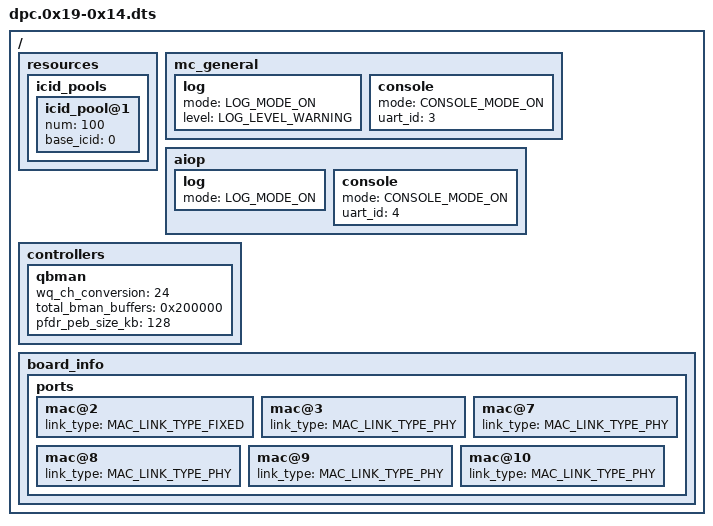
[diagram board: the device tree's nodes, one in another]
/*
 * Copyright 2017 NXP
 *
 * Redistribution and use in source and binary forms, with or without
 * modification, are permitted provided that the following conditions are met:
 *   * Redistributions of source code must retain the above copyright
 *     notice, this list of conditions and the following disclaimer.
 *   * Redistributions in binary form must reproduce the above copyright
 *     notice, this list of conditions and the following disclaimer in the
 *     documentation and/or other materials provided with the distribution.
 *   * Neither the name of the above-listed copyright holders nor the
 *     names of any contributors may be used to endorse or promote products
 *     derived from this software without specific prior written permission.
 *
 * THIS SOFTWARE IS PROVIDED BY THE COPYRIGHT HOLDERS AND CONTRIBUTORS "AS IS"
 * AND ANY EXPRESS OR IMPLIED WARRANTIES, INCLUDING, BUT NOT LIMITED TO, THE
 * IMPLIED WARRANTIES OF MERCHANTABILITY AND FITNESS FOR A PARTICULAR PURPOSE
 * ARE DISCLAIMED. IN NO EVENT SHALL THE COPYRIGHT HOLDERS OR CONTRIBUTORS BE
 * LIABLE FOR ANY DIRECT, INDIRECT, INCIDENTAL, SPECIAL, EXEMPLARY, OR
 * CONSEQUENTIAL DAMAGES (INCLUDING, BUT NOT LIMITED TO, PROCUREMENT OF
 * SUBSTITUTE GOODS OR SERVICES; LOSS OF USE, DATA, OR PROFITS; OR BUSINESS
 * INTERRUPTION) HOWEVER CAUSED AND ON ANY THEORY OF LIABILITY, WHETHER IN
 * CONTRACT, STRICT LIABILITY, OR TORT (INCLUDING NEGLIGENCE OR OTHERWISE)
 * ARISING IN ANY WAY OUT OF THE USE OF THIS SOFTWARE, EVEN IF ADVISED OF THE
 * POSSIBILITY OF SUCH DAMAGE.
 */
/dts-v1/;
/* DPC */
/ {
	resources {
		icid_pools {
			icid_pool@1 {
				num = <100>;
				base_icid = <0>;
			};
		};
	};
	mc_general {
		log {
			mode = "LOG_MODE_ON";
			level = "LOG_LEVEL_WARNING";
		};
		console {
			mode = "CONSOLE_MODE_ON";
			uart_id = <3>;
		};
	};
	aiop {
		log {
			mode = "LOG_MODE_ON";
		};
		console {
			mode = "CONSOLE_MODE_ON";
			uart_id = <4>;
		};
	};
	controllers {
		qbman {
			/* Transform this number of 8-WQ channels into four times
			 * as many 2-WQ channels. This allows the creation of a
			 * larger number of DPCONs.
			 */
			wq_ch_conversion = <24>;
			total_bman_buffers = <0x200000>;
			pfdr_peb_size_kb = <128>;
		};
	};
	board_info {
		ports {
			/* All ports have by default FIXED_LINK PHYs.
			 * Add "MAC_LINK_TYPE_PHY" properties for ports
			 * that have managed PHYs
			 */
			mac@2 {
				link_type = "MAC_LINK_TYPE_FIXED";
			};
			mac@3 {
				link_type = "MAC_LINK_TYPE_PHY";
			};
			mac@7 {
				link_type = "MAC_LINK_TYPE_PHY";
			};
			mac@8 {
				link_type = "MAC_LINK_TYPE_PHY";
			};
			mac@9 {
				link_type = "MAC_LINK_TYPE_PHY";
			};
			mac@10 {
				link_type = "MAC_LINK_TYPE_PHY";
			};
		};
	};
};
